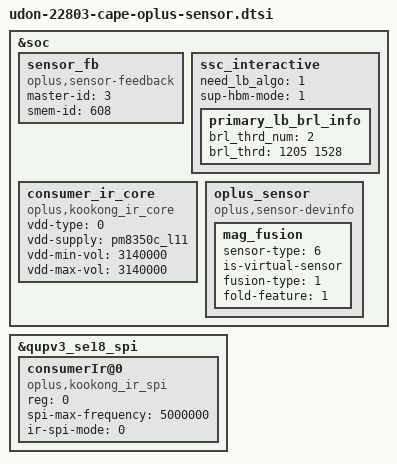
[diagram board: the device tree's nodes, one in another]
/**********************************************************************************
* Copyright (c)  2022-2024  Guangdong oplus Mobile Comm Corp., Ltd
* Description: oplus sensor dtsi
*
* Version: 1.0
* Date: 2022-09-20
*
* ------------------------------ Revision History: --------------------------------
* <version>         <date>        <author>                <desc>
***********************************************************************************/
&soc {
	//#ifdef OPLUS_FEATURE_SENSOR_SMEM
	sensor_fb: sensor_fb {
		compatible = "oplus,sensor-feedback";
		master-id  = <3>;
		smem-id    = <608>;
	};
	ssc_interactive {
		need_lb_algo = <1>;
		sup-hbm-mode = <1>;
		primary_lb_brl_info {
			brl_thrd_num = <2>;
			brl_thrd = <1205 1528>;
		};
	};
	consumer_ir_core: consumer_ir_core {
		compatible = "oplus,kookong_ir_core";
		status = "okay";

		vdd-type = <0>; /*0: internal LDO , 1: external LOD*/
		vdd-supply = <&pm8350c_l11>;
		vdd-min-vol = <3140000>;
		vdd-max-vol = <3140000>;
	};
	oplus_sensor {
		compatible = "oplus,sensor-devinfo";
		/*virtual sensor*/
		mag_fusion {
			sensor-type = <6>;//OPLUS_MAG_FUSION
			is-virtual-sensor;
			fusion-type = <1>;//AKM_FUSION
			fold-feature = <1>;
		};
	};
	//#endif /*OPLUS_FEATURE_SENSOR_SMEM*/
};

//add for oplus consumerIr SPI mode
&qupv3_se18_spi{
	status = "ok";
	consumerIr@0 {
		compatible = "oplus,kookong_ir_spi";
		reg = <0>;
		status = "ok";

		spi-max-frequency = <5000000>;    /*4800000,9600000,15000000,19200000*/
		ir-spi-mode = <0>;
	};
};
